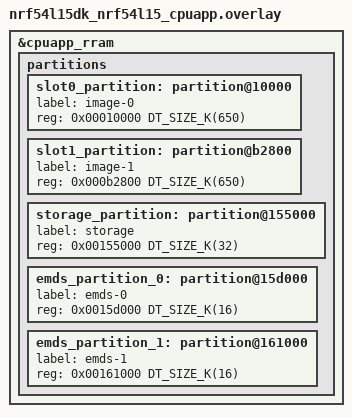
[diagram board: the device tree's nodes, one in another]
/delete-node/ &storage_partition;
/delete-node/ &slot0_partition;
/delete-node/ &slot1_partition;

&cpuapp_rram {
	partitions {
		slot0_partition: partition@10000 {
			label = "image-0";
			reg = <0x00010000 DT_SIZE_K(650)>;
		};

		slot1_partition: partition@b2800 {
			label = "image-1";
			reg = <0x000b2800 DT_SIZE_K(650)>;
		};

		storage_partition: partition@155000 {
			label = "storage";
			reg = <0x00155000 DT_SIZE_K(32)>;
		};

		emds_partition_0: partition@15d000 {
			label = "emds-0";
			reg = <0x0015d000 DT_SIZE_K(16)>;
		};

		emds_partition_1: partition@161000 {
			label = "emds-1";
			reg = <0x00161000 DT_SIZE_K(16)>;
		};
	};
};
